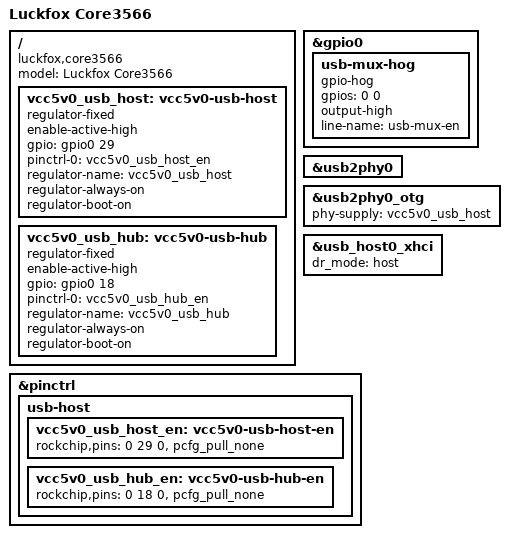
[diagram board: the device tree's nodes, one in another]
// SPDX-License-Identifier: (GPL-2.0+ OR MIT)
/dts-v1/;
/plugin/;

/ {
   model = "Luckfox Core3566";
   compatible = "luckfox,core3566", "rockchip,rk3566";
   #address-cells = <2>;
   #size-cells = <2>;

   fragment@0 {
      target-path = "/";
      __overlay__ {
         vcc5v0_usb_host: vcc5v0-usb-host {
            compatible = "regulator-fixed";
            enable-active-high;
            gpio = <&gpio0 29 0>; /* RK_PD5 */
            pinctrl-names = "default";
            pinctrl-0 = <&vcc5v0_usb_host_en>;
            regulator-name = "vcc5v0_usb_host";
            regulator-always-on;
            regulator-boot-on;
         };

         vcc5v0_usb_hub: vcc5v0-usb-hub {
            compatible = "regulator-fixed";
            enable-active-high;
            gpio = <&gpio0 18 0>; /* RK_PC2 */
            pinctrl-names = "default";
            pinctrl-0 = <&vcc5v0_usb_hub_en>;
            regulator-name = "vcc5v0_usb_hub";
            regulator-always-on;
            regulator-boot-on;
         };
      };
   };

   fragment@1 {
      target = <&gpio0>;
      __overlay__ {
         usb-mux-hog {
            gpio-hog;
            gpios = <0 0>; /* RK_PA0 */
            output-high;
            line-name = "usb-mux-en";
         };
      };
   };

   fragment@2 {
      target = <&usb2phy0>;
      __overlay__ {
         status = "okay";
      };
   };

   fragment@3 {
      target = <&usb2phy0_otg>;
      __overlay__ {
         status = "okay";
         phy-supply = <&vcc5v0_usb_host>;
      };
   };

   fragment@4 {
      target = <&usb_host0_xhci>;
      __overlay__ {
         status = "okay";
         dr_mode = "host";
      };
   };

   fragment@5 {
      target = <&pinctrl>;
      __overlay__ {
         usb-host {
            vcc5v0_usb_host_en: vcc5v0-usb-host-en {
               rockchip,pins = <0 29 0 &pcfg_pull_none>;
            };
            vcc5v0_usb_hub_en: vcc5v0-usb-hub-en {
               rockchip,pins = <0 18 0 &pcfg_pull_none>;
            };
         };
      };
   };
};
